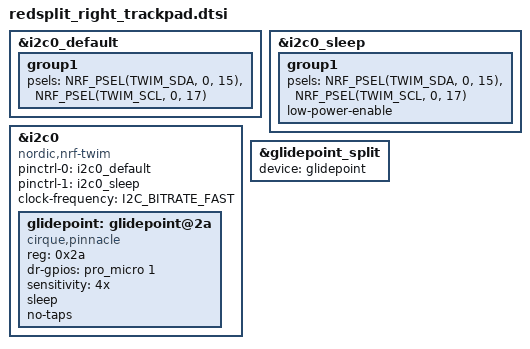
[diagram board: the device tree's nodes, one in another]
#include "redsplit.dtsi"

&i2c0_default {
  group1 {
    psels = <NRF_PSEL(TWIM_SDA, 0, 15)>,
        <NRF_PSEL(TWIM_SCL, 0, 17)>;
  };
};

&i2c0_sleep{
  group1 {
    psels = <NRF_PSEL(TWIM_SDA, 0, 15)>,
        <NRF_PSEL(TWIM_SCL, 0, 17)>;
    low-power-enable;
  };
};

cirque_pinnacle_i2c: &i2c0 {
    compatible = "nordic,nrf-twim";
    pinctrl-0 = <&i2c0_default>;
    pinctrl-1 = <&i2c0_sleep>;
    pinctrl-names = "default", "sleep";
    clock-frequency = <I2C_BITRATE_FAST>;
};

&cirque_pinnacle_i2c {
    status = "okay";

    glidepoint: glidepoint@2a {
        compatible = "cirque,pinnacle";
        reg = <0x2a>;
        status = "okay";
        dr-gpios = <&pro_micro 1 (GPIO_ACTIVE_HIGH)>;
        sensitivity = "4x";
        sleep; 
        no-taps;
    };
};

&glidepoint {
	status = "okay";
};

&glidepoint_split {
	device = <&glidepoint>;
};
